# V32F20x_CM33 register map
File version: 1.0.3
CPU: CM33 r0p4, little endian, MPU, FPU, DSP, 3 interrupt priority bits, 8 SAU regions
Registers are 32-bit, read-write, reset 0x0 unless marked. A register's access mark holds for its fields unless they carry their own. Offsets are from the block's base; [hi:lo] are bit positions; {n}, {i} and the like mark numbered series.

## I2C0 — I2C0 Peripheral Interface
Base 0x40010000; alternate view of UART0
Same registers: I2C{n} {0x40010000+0x800*n} (alternate view of UART{n}) (n=1..13), I2C14 0x41010000, SEC_I2C{n} {0x50010000+0x800*n} (alternate view of SEC_UART{n}) (n=0..13)
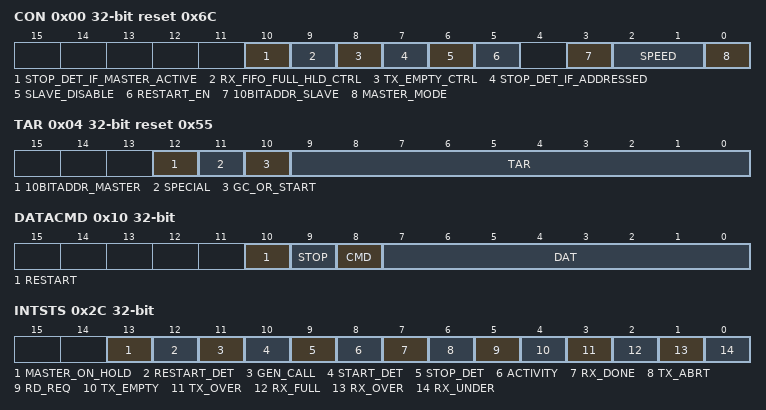
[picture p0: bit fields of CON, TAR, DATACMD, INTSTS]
0x00 CON reset 0x6C — I2C control register.
  [10] STOP_DET_IF_MASTER_ACTIVE — In Master mode:
  [9] RX_FIFO_FULL_HLD_CTRL — This bit controls whether I2C should hold the bus when the Rx FIFO is physically full to its RX_BUFFER_DEPTH
  [8] TX_EMPTY_CTRL — This bit controls the generation of the TX_EMPTY interrupt as described in the I2C_RAWINTSTS register
  [7] STOP_DET_IF_ADDRESSED — In slave mode:
  [6] SLAVE_DISABLE — This bit controls whether I2C has its slave disabled then this bit takes on the value of the configuration parameter I2C_SLAVE_DISABLE
  [5] RESTART_EN — Determines whether RESTART conditions may be sent when acting as a master
  [3] 10BITADDR_SLAVE — When acting as a slave this bit controls whether the I2C responds to 7 or 10 bit addresses
  [2:1] SPEED — These bits control at which speed the I2C operates its setting is relevant only if one is operating the I2C in master mode
  [0] MASTER_MODE — This bit controls whether the I2C master is enabled
0x04 TAR reset 0x55 — I2C target address register.
  [12] 10BITADDR_MASTER — This bit controls whether the I2C starts its transfers in 7 or 10 bit addressing mode when acting as a master
  [11] SPECIAL — This bit indicates whether software performs a Device ID or General Call or START BYTE command
  [10] GC_OR_START — If bit 11 SPECIAL is set to 1 and bit 13 Device ID is set to 0 then this bit indicates whether a General Call or START byte command is to be performed by the I2C
  [9:0] TAR — This is the target address for any master transaction
0x08 SAR reset 0x55 — I2C slave address register.
  [9:0] SAR — The I2C_SAR holds the slave address when the I2C is operating as a slave
0x10 DATACMD — I2C Rx/Tx data buffer and command register.
  [10] RESTART — This bit controls whether a RESTART is issued before the byte is sent or received
  [9] STOP — This bit controls whether a STOP is issued after the byte is sent or received
  [8] CMD — This bit controls whether a read or a write is performed
  [7:0] DAT — This register contains the data to be transmitted or received on the I2C bus
0x14 SSCNTH reset 0x28 — Standard speed I2C clock SCL high count register.
  [15:0] SS_SCL_HCNT — This register must be set before any I2C bus transaction can take place to ensure proper I O timing
0x18 SSCNTL reset 0x2F — Standard speed I2C clock SCL low count register.
  [15:0] SS_SCL_LCNT — This register must be set before any I2C bus transaction can take place to ensure proper I O timing
0x1C FSCNTH reset 0x6 — Fast Mode or Fast Mode Plus I2C clock SCL high count register
  [15:0] FS_SCL_HCNT — This register must be set before any I2C bus transaction can take place to ensure proper I O timing
0x20 FSCNTL reset 0xD — Fast Mode or Fast Mode Plus I2C clock SCL low count register
  [15:0] FS_SCL_LCNT — This register must be set before any I2C bus transaction can take place to ensure proper I O timing
0x2C INTSTS ro — I2C interrupt status register.
  [13] MASTER_ON_HOLD — See I2C_RAWINTSTS for a detailed description of MASTER_ON_HOLD bit
  [12] RESTART_DET — See I2C_RAWINTSTS for a detailed description of RESTART_DET bit
  [11] GEN_CALL — See I2C_RAWINTSTS for a detailed description of GEN_CALL bit
  [10] START_DET — See I2C_RAWINTSTS for a detailed description of START_DET bit
  [9] STOP_DET — See I2C_RAWINTSTS for a detailed description of STOP_DET bit
  [8] ACTIVITY — See I2C_RAWINTSTS for a detailed description of ACTIVITY bit
  [7] RX_DONE — See I2C_RAWINTSTS for a detailed description of R_RX_DONE bit
  [6] TX_ABRT — See I2C_RAWINTSTS for a detailed description of TX_ABRT bit
  [5] RD_REQ — See I2C_RAWINTSTS for a detailed description of RD_REQ bit
  [4] TX_EMPTY — See I2C_RAWINTSTS for a detailed description of TX_EMPTY bit
  [3] TX_OVER — See I2C_RAWINTSTS for a detailed description of TX_OVER bit
  [2] RX_FULL — See I2C_RAWINTSTS for a detailed description of RX_FULL bit
  [1] RX_OVER — See I2C_RAWINTSTS for a detailed description of RX_OVER bit
  [0] RX_UNDER — See I2C_RAWINTSTS for a detailed description of RX_UNDER bit
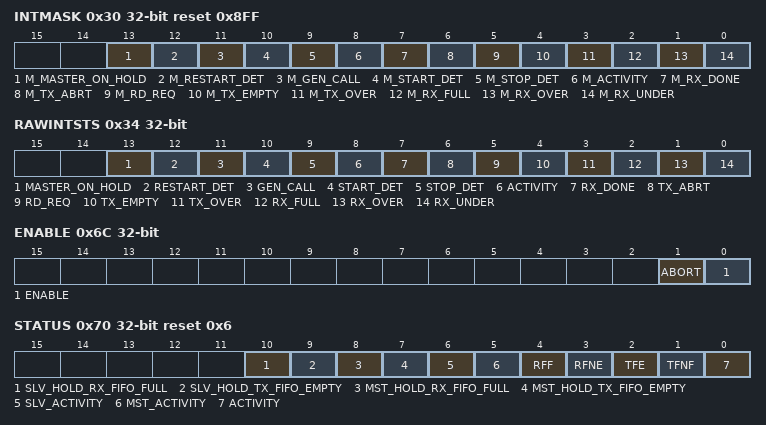
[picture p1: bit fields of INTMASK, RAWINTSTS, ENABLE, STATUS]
0x30 INTMASK reset 0x8FF — I2C interrupt mask register.
  [13] M_MASTER_ON_HOLD — This bit masks the R_MASTER_ON_HOLD interrupt in I2C_INTSTS register
  [12] M_RESTART_DET — This bit masks the R_RESTART_DET interrupt in I2C_INTSTS register
  [11] M_GEN_CALL — This bit masks the R_GEN_CALL interrupt in I2C_INTSTS register
  [10] M_START_DET — This bit masks the R_START_DET interrupt in I2C_INTSTS register
  [9] M_STOP_DET — This bit masks the R_STOP_DET interrupt in I2C_INTSTS register
  [8] M_ACTIVITY — This bit masks the R_ACTIVITY interrupt in I2C_INTSTS register
  [7] M_RX_DONE — This bit masks the R_RX_DONE interrupt in I2C_INTSTS register
  [6] M_TX_ABRT — This bit masks the R_TX_ABRT interrupt in I2C_INTSTS register
  [5] M_RD_REQ — This bit masks the R_RD_REQ interrupt in I2C_INTSTS register
  [4] M_TX_EMPTY — This bit masks the R_TX_EMPTY interrupt in I2C_INTSTS register
  [3] M_TX_OVER — This bit masks the R_TX_OVER interrupt in I2C_INTSTS register
  [2] M_RX_FULL — This bit masks the R_RX_FULL interrupt in I2C_INTSTS register
  [1] M_RX_OVER — This bit masks the R_RX_OVER interrupt in I2C_INTSTS register
  [0] M_RX_UNDER — This bit masks the R_RX_UNDER interrupt in I2C_INTSTS register
0x34 RAWINTSTS ro — I2C raw interrupt status register.
  [13] MASTER_ON_HOLD — Indicates whether master is holding the bus and TX FIFO is empty
  [12] RESTART_DET — Indicates whether a RESTART condition has occurred on the I2C interface when I2C is operating in Slave mode and the slave is being addressed
  [11] GEN_CALL — Set only when a General Call address is received and it is acknowledged
  [10] START_DET — Indicates whether a START or RESTART condition has occurred on the I2C interface regardless of whether I2C is operating in slave or master mode
  [9] STOP_DET — Indicates whether a STOP condition has occurred on the I2C interface regardless of whether I2C is operating in slave or master mode
  [8] ACTIVITY — This bit captures I2C activity and stays set until it is cleared
  [7] RX_DONE — When the I2C is acting as a slave transmitter this bit is set to 1 if the master does not acknowledge a transmitted byte
  [6] TX_ABRT — This bit indicates if I2C as an I2C transmitter is unable to complete the intended actions on the contents of the transmit FIFO
  [5] RD_REQ — This bit is set to 1 when I2C is acting as a slave and another I2C master is attempting to read data from I2C
  [4] TX_EMPTY — The behavior of the TX_EMPTY interrupt status differs based on the TX_EMPTY_CTRL selection in the I2C_CON register
  [3] TX_OVER — Set during transmit if the transmit buffer is filled to I2C_TX_BUFFER_DEPTH and the processor attempts to issue another I2C command by writing to the I2C_DATACMD register
  [2] RX_FULL — Set when the receive buffer reaches or goes above the RX_TL threshold in the I2C_RXTL register
  [1] RX_OVER — Set if the receive buffer is completely filled to I2C_RX_BUFFER_DEPTH and an additional byte is received from an external I2C device
  [0] RX_UNDER — Set if the processor attempts to read the receive buffer when it is empty by reading from the I2C_DATACMD register
0x38 RXTL — I2C receive FIFO threshold register.
  [2:0] RX_TL — Receive FIFO Threshold Level.
0x3C TXTL — I2C transmit FIFO threshold register.
  [2:0] TX_TL — Transmit FIFO Threshold Level.
0x40 INTCLR ro — Clear combined and individual interrupt register.
  [0] CLR_INTR — Read this register to clear the combined interrupt all individual interrupts and the I2C_TXABTSRC register
0x44 RXUCLR ro — Clear RX_UNDER interrupt register.
  [0] CLR_RX_UNDER — Read this register to clear the RX_UNDER interrupt bit 0 of the I2C_RAWINTSTS register
0x48 RXOCLR ro — Clear RX_OVER interrupt register.
  [0] CLR_RX_OVER — Read this register to clear the RX_OVER interrupt bit 1 of the I2C_RAWINTSTS register
0x4C TXOCLR ro — Clear TX_OVER interrupt register.
  [0] CLR_TX_OVER — Read this register to clear the TX_OVER interrupt bit 3 of the I2C_RAWINTSTS register
0x50 RDREQCLR ro — Clear RD_REQ interrupt register.
  [0] CLR_RD_REQ — Read this register to clear the RD_REQ interrupt bit 5 of the I2C_RAWINTSTS register
0x54 TXABTCLR ro — Clear TX_ABRT interrupt register.
  [0] CLR_TX_ABRT — Read this register to clear the TX_ABRT interrupt bit 6 of the I2C_RAWINTSTS register and the I2C_TXABTSRC register
0x58 RXDONECLR ro — Clear RX_DONE interrupt register.
  [0] CLR_RX_DONE — Read this register to clear the RX_DONE interrupt bit 7 of the I2C_RAWINTSTS register
0x5C ACTCLR ro — Clear ACTIVITY interrupt register.
  [0] CLR_ACTIVITY — Reading this register clears the ACTIVITY interrupt if the I2C is not active anymore
0x60 STOPDETCLR ro — Clear STOP_DET interrupt register.
  [0] CLR_STOP_DET — Read this register to clear the STOP_DET interrupt bit 9 of the I2C_RAWINTSTS register
0x64 STARTDETCLR ro — Clear START_DET interrupt register.
  [0] CLR_START_DET — Read this register to clear the START_DET interrupt bit 10 of the I2C_RAWINTSTS register
0x68 GENCALLCLR ro — Clear GEN_CALL interrupt register.
  [0] CLR_GEN_CALL — Read this register to clear the GEN_CALL interrupt bit 11 of I2C_RAWINTSTS register
0x6C ENABLE — I2C enable register.
  [1] ABORT — When set the controller initiates the transfer abort
  [0] ENABLE — Controls whether the I2C is enabled.
0x70 STATUS ro reset 0x6 — I2C status register.
  [10] SLV_HOLD_RX_FIFO_FULL — This bit indicates the BUS Hold in Slave mode due to Rx FIFO is Full and an additional byte has been received
  [9] SLV_HOLD_TX_FIFO_EMPTY — This bit indicates the BUS Hold in Slave mode for the Read request when the Tx FIFO is empty
  [8] MST_HOLD_RX_FIFO_FULL — This bit indicates the BUS Hold in Master mode due to Rx FIFO is Full and additional byte has been received
  [7] MST_HOLD_TX_FIFO_EMPTY — The I2C master stalls the write transfer when Tx FIFO is empty and the the last byte does not have the Stop bit set
  [6] SLV_ACTIVITY — Slave FSM Activity Status
  [5] MST_ACTIVITY — Master FSM Activity Status
  [4] RFF — Receive FIFO Completely Full
  [3] RFNE — Receive FIFO Not Empty
  [2] TFE — Transmit FIFO Completely Empty
  [1] TFNF — Transmit FIFO Not Full
  [0] ACTIVITY — I2C Activity Status.
0x74 TXFLR ro — I2C transmit FIFO level register.
  [3:0] TXFLR — Transmit FIFO Level
0x78 RXFLR ro — I2C Receive FIFO Level Register.
  [3:0] RXFLR — Receive FIFO Level
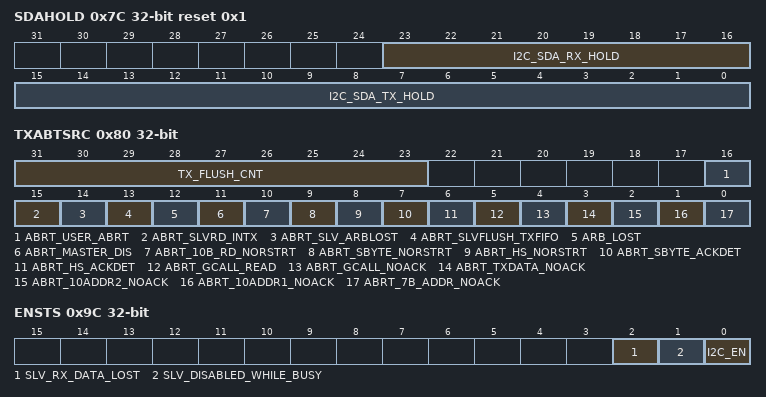
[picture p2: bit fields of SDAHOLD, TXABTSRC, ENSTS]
0x7C SDAHOLD reset 0x1 — I2C SDA hold time length register.
  [23:16] I2C_SDA_RX_HOLD — Sets the required SDA hold time in units of ic_clk period when I2C acts as a receiver
  [15:0] I2C_SDA_TX_HOLD — Sets the required SDA hold time in units of ic_clk period when I2C acts as a transmitter
0x80 TXABTSRC ro — I2C transmit abort source register.
  [31:23] TX_FLUSH_CNT — This field indicates the number of Tx FIFO Data Commands which are flushed due to TX_ABRT interrupt
  [16] ABRT_USER_ABRT — This is a master mode only bit
  [15] ABRT_SLVRD_INTX — 1 When the processor side responds to a slave mode request for data to be transmitted to a remote master and user writes a 1 in CMD bit 8 of I2C_DATACMD register
  [14] ABRT_SLV_ARBLOST — This field indicates that a Slave has lost the bus while transmitting data to a remote master
  [13] ABRT_SLVFLUSH_TXFIFO — This field specifies that the Slave has received a read command and some data exists in the TX FIFO so the slave issues a TX_ABRT interrupt to flush old data in TX FIFO
  [12] ARB_LOST — This field specifies that the Master has lost arbitration or if I2C_TXABTSRC 14 is also set then the slave transmitter has lost arbitration
  [11] ABRT_MASTER_DIS — This field indicates that the User tries to initiate a Master operation with the Master mode disabled
  [10] ABRT_10B_RD_NORSTRT — This field indicates that the restart is disabled I2C_RESTART_EN bit I2C_CON 5 0 and the master sends a read command in 10 bit addressing mode
  [9] ABRT_SBYTE_NORSTRT — To clear Bit 9 the source of the ABRT_SBYTE_NORSTRT must be fixed first restart must be enabled I2C_CON 5 1 the SPECIAL bit must be cleared I2C_TAR 11 or the GC_OR_START bit must be cleared I2C_TAR 10
  [8] ABRT_HS_NORSTRT — This field indicates that the restart is disabled I2C_RESTART_EN bit I2C_CON 5 0 and the user is trying to use the master to transfer data in High Speed mode
  [7] ABRT_SBYTE_ACKDET — This field indicates that the Master has sent a START Byte and the START Byte was acknowledged wrong behavior
  [6] ABRT_HS_ACKDET — This field indicates that the Master is in High Speed mode and the High Speed Master code was acknowledged wrong behavior
  [5] ABRT_GCALL_READ — This field indicates that I2C in the master mode has sent a General Call but the user programmed the byte following the General Call to be a read from the bus I2C_DATACMD 9 is set to 1
  [4] ABRT_GCALL_NOACK — This field indicates that I2C in master mode has sent a General Call and no slave on the bus acknowledged the General Call
  [3] ABRT_TXDATA_NOACK — This field indicates the master mode only bit
  [2] ABRT_10ADDR2_NOACK — This field indicates that the Master is in 10 bit address mode and that the second address byte of the 10 bit address was not acknowledged by any slave
  [1] ABRT_10ADDR1_NOACK — This field indicates that the Master is in 10 bit address mode and the first 10 bit address byte was not acknowledged by any slave
  [0] ABRT_7B_ADDR_NOACK — This field indicates that the Master is in 7 bit addressing mode and the address sent was not acknowledged by any slave
0x94 SDASETUP reset 0x64 — I2C SDA setup register.
  [7:0] SDA_SETUP
0x98 ACKGC reset 0x1 — I2C ACK General Call register.
  [0] ACK_GEN_CALL — ACK General Call
0x9C ENSTS ro — I2C enable status register.
  [2] SLV_RX_DATA_LOST — Slave Received Data Lost
  [1] SLV_DISABLED_WHILE_BUSY — Slave Disabled While Busy Transmit Receive
  [0] I2C_EN — ic_en Status
0xA0 SPKLEN reset 0x1 — I2C SS, FS or FM+ spike suppression limit register
  [7:0] FS_SPKLEN — This register must be set before any I2C bus transaction can take place to ensure stable operation
0xA8 RESDETCLR ro — Clear RESTART_DET interrupt register.
  [0] CLR_RESTART_DET — Read this register to clear the RESTART_DET interrupt bit 12 of I2C_RAWINTSTS register
